# MEC1322 register map
Vendor: Microchip Technology Inc.; Series: ARMCM4F; File version: 1.0
CPU: CM4 r1p0, little endian, MPU, FPU, 3 interrupt priority bits
Registers are 32-bit, read-write, reset 0x0 unless marked. A register's access mark holds for its fields unless they carry their own. Offsets are from the block's base; [hi:lo] are bit positions; {n}, {i} and the like mark numbered series.

## EMI — The Embedded Memory Interface (EMI) provides a standard run-time mechanism for the system host to communicate with the Embedded Controller (EC) and other logical components.
Base 0x400F0000
0x00 HOST_EC_MBX 8-bit — Host-to-EC Mailbox Register
0x01 EC_HOST_MBX 8-bit — EC-to-Host Mailbox Register
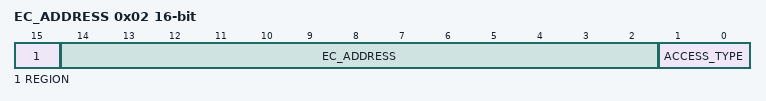
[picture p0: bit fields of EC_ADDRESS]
0x02 EC_ADDRESS 16-bit — EC Address Access Control Register
  [15] REGION — 1= The address defined by EC_Address[14:2] is relative to the base address specified by the Memory Base Address 1 Register. 0= The address defined by EC_Address[14:2] is relative to the base address specified by the Memory Base Address 0 Register.
  [14:2] EC_ADDRESS — This field defines bits[14:2] of EC_Address [15:0]. Bits[1:0] of the EC_Address are always forced to 00b.
  [1:0] ACCESS_TYPE — This field defines the type of access that occurs when the EC Data Register is read or written. 11b=Auto-increment 32-bit access. 10b=32-bit access. 01b=16-bit access. 00b=8-bit access.
{0x4+i} EC_DATA_BYTE[{i}] (i=0..3) 8-bit
0x04 EC_DATA (alternate view of EC_DATA_BYTE0)
0x08 EC_SWI 16-bit — [0:0] EC_WR EC Mailbox Write. This bit is set when the EC-to-HOST Mailbox Register has been written by the EC at offset 01h of the EC-Only registers.(read-only) [15:1] EC Software Interrupt Least Significant Bits. These bits are software interrupt bits that may be set by the EC to notify the host of an event. The meaning of these bits is dependent on the firmware implementation. (R/WC)
0x0A EC_SWI_EN 16-bit — [15:1] Each bit that is set to '1b' in this field enables the generation of a Host Event interrupt by the corresponding bit in the EC_SWI field in the Interrupt Source Register
0x0C APPLICATION_ID 8-bit — Application ID Register, APPLICATION_ID When this field is 00h it can be written with any value. When set to a non-zero value, writing that value will clear this register to 00h. When set to a non-zero value, writing any value other than the current contents will have no effect.
0x100 HOST2EC_MBX 8-bit — Host-to-EC Mailbox Register, 8-bit mailbox used communicate information from the system host to the embedded controller. Writing this register generates an event to notify the embedded controller. (R/WC)
0x101 EC2HOST_MBX 8-bit — EC-to-Host Mailbox Register, 8-bit mailbox used communicate information from the embedded controller to the system host. Writing this register generates an event to notify the system host.
0x104 MEMORY_BASE_ADDRESS_0 — Memory Base Address 0 Register [31:2] This memory base address defines the beginning of region 0 in the Embedded Controller's 32-bit internal address space. Memory allocated to region 0 is intended to be shared between the Host and the EC. The region defined by this base register is used when bit 15 of the EC Address Register is 0. The access will be to a memory location at an offset defined by the EC_Address relative to the beginning of the region defined by this register. Therefore, a read or write to the memory that is triggered by the EC Data Register will occur at Memory_Base_Address_0 + EC_Address.
0x108 MEMORY_READ_LIMIT_0 16-bit — Memory Read Limit 0 Register [14:2] Whenever a read of any byte in the EC Data Register is attempted, and bit 15 of EC_Address is 0, the field EC_Address[14:2] in the EC_Address_Register is compared to this field. As long as EC_Address[14:2] is less than this field the EC_Data_Register will be loaded from the 24-bit internal address space.
0x10A MEMORY_WRITE_LIMIT_0 16-bit — Memory Write Limit 0 Register [14:2] Whenever a write of any byte in EC DATA Register is attempted and bit 15 of EC_Address is 0, the field EC_ADDRESS_MSB in the EC_Address Register is compared to this field. As long as EC_Address[14:2] is less than Memory_Write_Limit_0[14:2] the addressed bytes in the EC DATA Register will be written into the internal 24-bit address space. If EC_Address[14:2] is greater than or equal to the Memory_Write_Limit_0[14:2] no writes will take place.
0x10C MEMORY_BASE_ADDRESS_1 (reset mask 0xFFFF) — Memory Base Address 1 Register. [31:2] This memory base address defines the beginning of region 1 in the Embedded Controller's 32-bit internal address space. Memory allocated to region 1 is intended to be shared between the Host and the EC. The region defined by this base register is used when bit 15 of the EC Address Register is 1. The access will be to a memory location at an offset defined by the EC_Address relative to the beginning of the region defined by this register. Therefore, a read or write to the memory that is triggered by the EC Data Register will occur at Memory_Base_Address_1 + EC_Address.
0x110 MEMORY_READ_LIMIT_1 16-bit — Memory Read Limit 1 Register, [14:2]: Whenever a read of any byte in the EC Data Register is attempted, and bit 15 of EC_ADDRESS is 1, the field EC_ADDRESS in the EC_Address_Register is compared to this field. As long as EC_ADDRESS is less than this value, the EC_Data_Register will be loaded from the 24-bit internal address space.
0x112 MEMORY_WRITE_LIMIT_1 16-bit — Memory Write Limit 1 Register, [14:2]: Whenever a write of any byte in EC DATA Register is attempted and bit 15 of EC_Address is 1, the field EC_Address[14:2] in the EC_Address Register is compared to this field. As long as EC_Address[14:2] is less than Memory_Write_Limit_1[14:2] the addressed bytes in the EC DATA Register will be written into the internal 24-bit address space. If EC_Address[14:2] is greater than or equal to the Memory_Write_Limit_1[14:2] no writes will take place.
0x114 EC_SWI_SET 16-bit — [15:1] Interrupt Set Register, Writing a bit in this field with a '1b' sets the corresponding bit in the Interrupt Source Register to '1b'. Writing a bit in this field with a '0b' has no effect. Reading this field returns the current contents of the Interrupt Source Register.
0x116 CLEAR_ENABLE 16-bit — [15:1] Host Clear Enable Register, When a bit in this field is '0b', the corresponding bit in the Interrupt Source Register cannot be cleared by writes to the Interrupt Source Register. When a bit in this field is '1b', the corresponding bit in the Interrupt Source Register can be cleared when that register bit is written with a '1b'.
